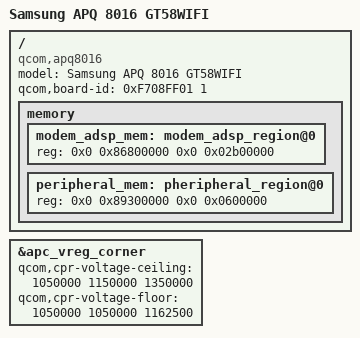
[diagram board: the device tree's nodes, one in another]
/* Copyright (c) 2014, The Linux Foundation. All rights reserved.
*
* This program is free software; you can redistribute it and/or modify
* it under the terms of the GNU General Public License version 2 and
* only version 2 as published by the Free Software Foundation.
*
* This program is distributed in the hope that it will be useful,
* but WITHOUT ANY WARRANTY; without even the implied warranty of
* MERCHANTABILITY or FITNESS FOR A PARTICULAR PURPOSE.  See the
* GNU General Public License for more details.
*/

/dts-v1/;

#include "gt58wifi/msm8916-gt58wifi.dtsi"
#include "samsung/msm8916-memory.dtsi"

/ {
	model = "Samsung APQ 8016 GT58WIFI";
	compatible = "qcom,apq8016", "qcom,mtp";
	qcom,board-id = <0xF708FF01 1>;

	memory {
		modem_adsp_mem: modem_adsp_region@0 {
			reg = <0x0 0x86800000 0x0 0x02b00000>;
		};

		peripheral_mem: pheripheral_region@0 {
			reg = <0x0 0x89300000 0x0 0x0600000>;
		};
	};

};

/*overwrite s2 cpr voltage for model variant*/
&apc_vreg_corner {
	qcom,cpr-voltage-ceiling = <1050000 1150000 1350000>;
        qcom,cpr-voltage-floor = <1050000 1050000 1162500>;
};
